AUTOSAR XML (schema 4-2-2)
package /STELLANTIS/EPT/ASWCs
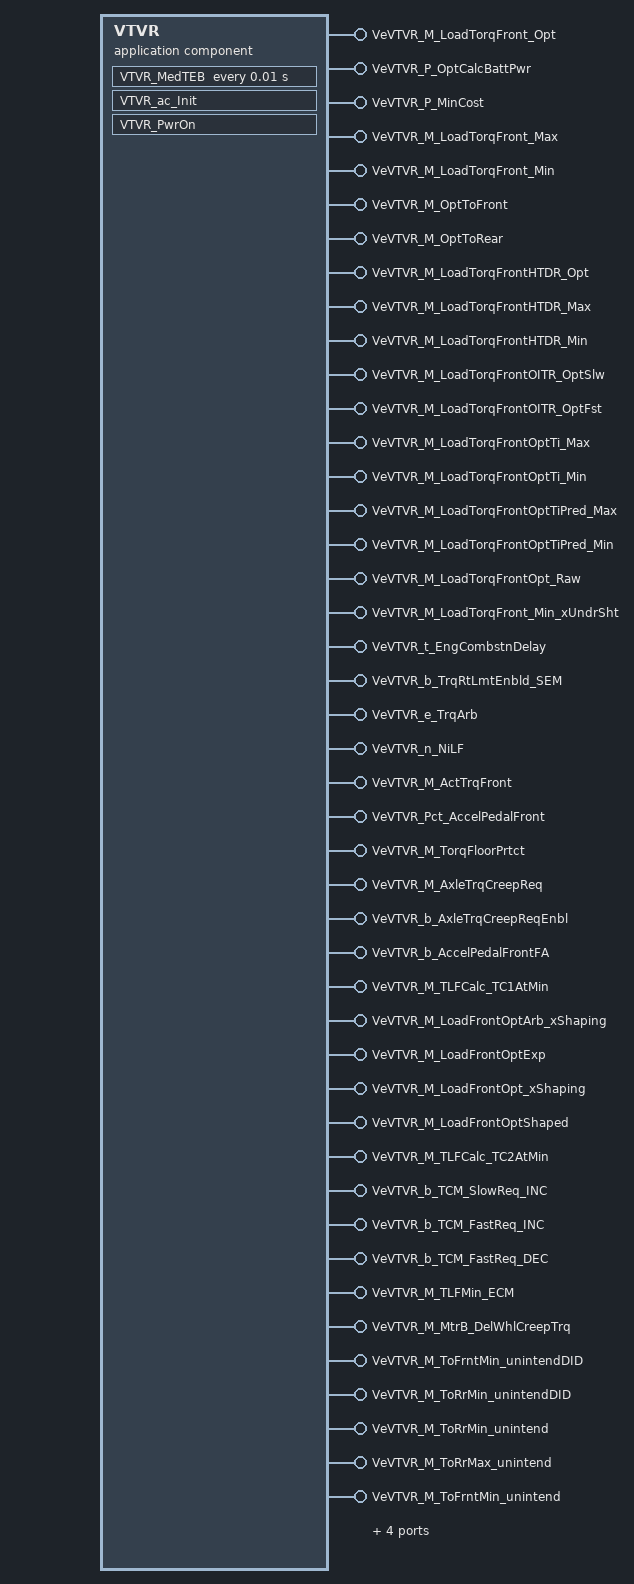
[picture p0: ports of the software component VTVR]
  application sw component type VTVR
    48 x provide port:
      VeVTVR_M_LoadTorqFront_Opt: nonqueued-sender-com-spec{data-element=Value, init-value=0}, provided-interface=VeVTVR_M_LoadTorqFront_Opt
      VeVTVR_P_OptCalcBattPwr: nonqueued-sender-com-spec{data-element=Value, init-value=0}, provided-interface=VeVTVR_P_OptCalcBattPwr
      VeVTVR_P_MinCost: nonqueued-sender-com-spec{data-element=Value, init-value=0}, provided-interface=VeVTVR_P_MinCost
      VeVTVR_M_LoadTorqFront_Max: nonqueued-sender-com-spec{data-element=Value, init-value=0}, provided-interface=VeVTVR_M_LoadTorqFront_Max
      VeVTVR_M_LoadTorqFront_Min: nonqueued-sender-com-spec{data-element=Value, init-value=0}, provided-interface=VeVTVR_M_LoadTorqFront_Min
      VeVTVR_M_OptToFront: nonqueued-sender-com-spec{data-element=Value, init-value=0}, provided-interface=VeVTVR_M_OptToFront
      VeVTVR_M_OptToRear: nonqueued-sender-com-spec{data-element=Value, init-value=0}, provided-interface=VeVTVR_M_OptToRear
      VeVTVR_M_LoadTorqFrontHTDR_Opt: nonqueued-sender-com-spec{data-element=Value, init-value=0}, provided-interface=VeVTVR_M_LoadTorqFrontHTDR_Opt
      VeVTVR_M_LoadTorqFrontHTDR_Max: nonqueued-sender-com-spec{data-element=Value, init-value=0}, provided-interface=VeVTVR_M_LoadTorqFrontHTDR_Max
      VeVTVR_M_LoadTorqFrontHTDR_Min: nonqueued-sender-com-spec{data-element=Value, init-value=0}, provided-interface=VeVTVR_M_LoadTorqFrontHTDR_Min
      VeVTVR_M_LoadTorqFrontOITR_OptSlw: nonqueued-sender-com-spec{data-element=Value, init-value=0}, provided-interface=VeVTVR_M_LoadTorqFrontOITR_OptSlw
      VeVTVR_M_LoadTorqFrontOITR_OptFst: nonqueued-sender-com-spec{data-element=Value, init-value=0}, provided-interface=VeVTVR_M_LoadTorqFrontOITR_OptFst
      VeVTVR_M_LoadTorqFrontOptTi_Max: nonqueued-sender-com-spec{data-element=Value, init-value=0}, provided-interface=VeVTVR_M_LoadTorqFrontOptTi_Max
      VeVTVR_M_LoadTorqFrontOptTi_Min: nonqueued-sender-com-spec{data-element=Value, init-value=0}, provided-interface=VeVTVR_M_LoadTorqFrontOptTi_Min
      VeVTVR_M_LoadTorqFrontOptTiPred_Max: nonqueued-sender-com-spec{data-element=Value, init-value=0}, provided-interface=VeVTVR_M_LoadTorqFrontOptTiPred_Max
      VeVTVR_M_LoadTorqFrontOptTiPred_Min: nonqueued-sender-com-spec{data-element=Value, init-value=0}, provided-interface=VeVTVR_M_LoadTorqFrontOptTiPred_Min
      VeVTVR_M_LoadTorqFrontOpt_Raw: nonqueued-sender-com-spec{data-element=Value, init-value=0}, provided-interface=VeVTVR_M_LoadTorqFrontOpt_Raw
      VeVTVR_M_LoadTorqFront_Min_xUndrSht: nonqueued-sender-com-spec{data-element=Value, init-value=0}, provided-interface=VeVTVR_M_LoadTorqFront_Min_xUndrSht
      VeVTVR_t_EngCombstnDelay: nonqueued-sender-com-spec{data-element=Value, init-value=0}, provided-interface=VeVTVR_t_EngCombstnDelay
      VeVTVR_b_TrqRtLmtEnbld_SEM: nonqueued-sender-com-spec{data-element=Value, init-value=0}, provided-interface=VeVTVR_b_TrqRtLmtEnbld_SEM
      VeVTVR_e_TrqArb: nonqueued-sender-com-spec{data-element=Value, init-value=CeWTAR_e_ECM_TorqReqst}, provided-interface=VeVTVR_e_TrqArb
      VeVTVR_n_NiLF: nonqueued-sender-com-spec{data-element=Value, init-value=0}, provided-interface=VeVTVR_n_NiLF
      VeVTVR_M_ActTrqFront: nonqueued-sender-com-spec{data-element=Value, init-value=0}, provided-interface=VeVTVR_M_ActTrqFront
      VeVTVR_Pct_AccelPedalFront: nonqueued-sender-com-spec{data-element=Value, init-value=0}, provided-interface=VeVTVR_Pct_AccelPedalFront
      VeVTVR_M_TorqFloorPrtct: nonqueued-sender-com-spec{data-element=Value, init-value=0}, provided-interface=VeVTVR_M_TorqFloorPrtct
      VeVTVR_M_AxleTrqCreepReq: nonqueued-sender-com-spec{data-element=Value, init-value=0}, provided-interface=VeVTVR_M_AxleTrqCreepReq
      VeVTVR_b_AxleTrqCreepReqEnbl: nonqueued-sender-com-spec{data-element=Value, init-value=0}, provided-interface=VeVTVR_b_AxleTrqCreepReqEnbl
      VeVTVR_b_AccelPedalFrontFA: nonqueued-sender-com-spec{data-element=Value, init-value=0}, provided-interface=VeVTVR_b_AccelPedalFrontFA
      VeVTVR_M_TLFCalc_TC1AtMin: nonqueued-sender-com-spec{data-element=Value, init-value=0}, provided-interface=VeVTVR_M_TLFCalc_TC1AtMin
      VeVTVR_M_LoadFrontOptArb_xShaping: nonqueued-sender-com-spec{data-element=Value, init-value=0}, provided-interface=VeVTVR_M_LoadFrontOptArb_xShaping
      VeVTVR_M_LoadFrontOptExp: nonqueued-sender-com-spec{data-element=Value, init-value=0}, provided-interface=VeVTVR_M_LoadFrontOptExp
      VeVTVR_M_LoadFrontOpt_xShaping: nonqueued-sender-com-spec{data-element=Value, init-value=0}, provided-interface=VeVTVR_M_LoadFrontOpt_xShaping
      VeVTVR_M_LoadFrontOptShaped: nonqueued-sender-com-spec{data-element=Value, init-value=0}, provided-interface=VeVTVR_M_LoadFrontOptShaped
      VeVTVR_M_TLFCalc_TC2AtMin: nonqueued-sender-com-spec{data-element=Value, init-value=0}, provided-interface=VeVTVR_M_TLFCalc_TC2AtMin
      VeVTVR_b_TCM_SlowReq_INC: nonqueued-sender-com-spec{data-element=Value, init-value=0}, provided-interface=VeVTVR_b_TCM_SlowReq_INC
      VeVTVR_b_TCM_FastReq_INC: nonqueued-sender-com-spec{data-element=Value, init-value=0}, provided-interface=VeVTVR_b_TCM_FastReq_INC
      VeVTVR_b_TCM_FastReq_DEC: nonqueued-sender-com-spec{data-element=Value, init-value=0}, provided-interface=VeVTVR_b_TCM_FastReq_DEC
      VeVTVR_M_TLFMin_ECM: nonqueued-sender-com-spec{data-element=Value, init-value=0}, provided-interface=VeVTVR_M_TLFMin_ECM
      VeVTVR_M_MtrB_DelWhlCreepTrq: nonqueued-sender-com-spec{data-element=Value, init-value=0}, provided-interface=VeVTVR_M_MtrB_DelWhlCreepTrq
      VeVTVR_M_ToFrntMin_unintendDID: nonqueued-sender-com-spec{data-element=Value, init-value=0}, provided-interface=VeVTVR_M_ToFrntMin_unintendDID
      VeVTVR_M_ToRrMin_unintendDID: nonqueued-sender-com-spec{data-element=Value, init-value=0}, provided-interface=VeVTVR_M_ToRrMin_unintendDID
      VeVTVR_M_ToRrMin_unintend: nonqueued-sender-com-spec{data-element=Value, init-value=0}, provided-interface=VeVTVR_M_ToRrMin_unintend
      VeVTVR_M_ToRrMax_unintend: nonqueued-sender-com-spec{data-element=Value, init-value=0}, provided-interface=VeVTVR_M_ToRrMax_unintend
      VeVTVR_M_ToFrntMin_unintend: nonqueued-sender-com-spec{data-element=Value, init-value=0}, provided-interface=VeVTVR_M_ToFrntMin_unintend
      VeVTVR_M_ToFrntMax_unintend: nonqueued-sender-com-spec{data-element=Value, init-value=0}, provided-interface=VeVTVR_M_ToFrntMax_unintend
      VeVTVR_M_SumTrqMin_Cruise: nonqueued-sender-com-spec{data-element=Value, init-value=0}, provided-interface=VeVTVR_M_SumTrqMin_Cruise
      VeVTVR_M_OutTorqReqModTactMax: nonqueued-sender-com-spec{data-element=Value, init-value=0}, provided-interface=VeVTVR_M_OutTorqReqModTactMax
      VeVTVR_M_OutTorqReqModTactMin: nonqueued-sender-com-spec{data-element=Value, init-value=0}, provided-interface=VeVTVR_M_OutTorqReqModTactMin
    behavior IB_VTVR: data-type-mapping=msADTtoIDTMapping, handle-termination-and-restart=NO-SUPPORT, included-data-type-set=data-type=[TeOPTR_e_OptType, TeTSXR_e_PrfrdComb]
      timing event Event_MedTEB: start-on-event=VTVR_MedTEB, period=0.01
      init event Event_VTVR_ac_Init: start-on-event=VTVR_ac_Init
      init event Event_PwrOn: start-on-event=VTVR_PwrOn
      runnable VTVR_ac_Init
        data-send-points:
          access OUT_VeVTVR_M_TLFCalc_TC1AtMin_Value: accessed-variable=VeVTVR_M_TLFCalc_TC1AtMin.Value
          access OUT_VeVTVR_e_TrqArb_Value: accessed-variable=VeVTVR_e_TrqArb.Value
      runnable VTVR_PwrOn
        data-send-points:
          48 x access:
            OUT_VeVTVR_M_ActTrqFront_Value: accessed-variable=VeVTVR_M_ActTrqFront.Value
            OUT_VeVTVR_Pct_AccelPedalFront_Value: accessed-variable=VeVTVR_Pct_AccelPedalFront.Value
            OUT_VeVTVR_M_OptToFront_Value: accessed-variable=VeVTVR_M_OptToFront.Value
            OUT_VeVTVR_M_OptToRear_Value: accessed-variable=VeVTVR_M_OptToRear.Value
            OUT_VeVTVR_n_NiLF_Value: accessed-variable=VeVTVR_n_NiLF.Value
            OUT_VeVTVR_M_AxleTrqCreepReq_Value: accessed-variable=VeVTVR_M_AxleTrqCreepReq.Value
            OUT_VeVTVR_b_AxleTrqCreepReqEnbl_Value: accessed-variable=VeVTVR_b_AxleTrqCreepReqEnbl.Value
            OUT_VeVTVR_b_AccelPedalFrontFA_Value: accessed-variable=VeVTVR_b_AccelPedalFrontFA.Value
            OUT_VeVTVR_M_LoadFrontOptShaped_Value: accessed-variable=VeVTVR_M_LoadFrontOptShaped.Value
            OUT_VeVTVR_M_TLFCalc_TC1AtMin_Value: accessed-variable=VeVTVR_M_TLFCalc_TC1AtMin.Value
            OUT_VeVTVR_b_TrqRtLmtEnbld_SEM_Value: accessed-variable=VeVTVR_b_TrqRtLmtEnbld_SEM.Value
            OUT_VeVTVR_t_EngCombstnDelay_Value: accessed-variable=VeVTVR_t_EngCombstnDelay.Value
            OUT_VeVTVR_M_LoadTorqFront_Min_xUndrSht_Value: accessed-variable=VeVTVR_M_LoadTorqFront_Min_xUndrSht.Value
            OUT_VeVTVR_M_LoadTorqFrontOpt_Raw_Value: accessed-variable=VeVTVR_M_LoadTorqFrontOpt_Raw.Value
            OUT_VeVTVR_M_TLFCalc_TC2AtMin_Value: accessed-variable=VeVTVR_M_TLFCalc_TC2AtMin.Value
            OUT_VeVTVR_M_LoadTorqFront_Min_Value: accessed-variable=VeVTVR_M_LoadTorqFront_Min.Value
            OUT_VeVTVR_M_LoadTorqFrontOITR_OptSlw_Value: accessed-variable=VeVTVR_M_LoadTorqFrontOITR_OptSlw.Value
            OUT_VeVTVR_M_TLFMin_ECM_Value: accessed-variable=VeVTVR_M_TLFMin_ECM.Value
            OUT_VeVTVR_M_MtrB_DelWhlCreepTrq_Value: accessed-variable=VeVTVR_M_MtrB_DelWhlCreepTrq.Value
            OUT_VeVTVR_M_LoadFrontOpt_xShaping_Value: accessed-variable=VeVTVR_M_LoadFrontOpt_xShaping.Value
            OUT_VeVTVR_M_ToFrntMin_unintendDID_Value: accessed-variable=VeVTVR_M_ToFrntMin_unintendDID.Value
            OUT_VeVTVR_M_LoadFrontOptExp_Value: accessed-variable=VeVTVR_M_LoadFrontOptExp.Value
            OUT_VeVTVR_M_ToRrMin_unintendDID_Value: accessed-variable=VeVTVR_M_ToRrMin_unintendDID.Value
            OUT_VeVTVR_M_ToRrMin_unintend_Value: accessed-variable=VeVTVR_M_ToRrMin_unintend.Value
            OUT_VeVTVR_M_ToRrMax_unintend_Value: accessed-variable=VeVTVR_M_ToRrMax_unintend.Value
            OUT_VeVTVR_M_ToFrntMin_unintend_Value: accessed-variable=VeVTVR_M_ToFrntMin_unintend.Value
            OUT_VeVTVR_M_ToFrntMax_unintend_Value: accessed-variable=VeVTVR_M_ToFrntMax_unintend.Value
            OUT_VeVTVR_M_SumTrqMin_Cruise_Value: accessed-variable=VeVTVR_M_SumTrqMin_Cruise.Value
            OUT_VeVTVR_M_LoadTorqFront_Max_Value: accessed-variable=VeVTVR_M_LoadTorqFront_Max.Value
            OUT_VeVTVR_M_LoadTorqFront_Opt_Value: accessed-variable=VeVTVR_M_LoadTorqFront_Opt.Value
            OUT_VeVTVR_M_LoadTorqFrontHTDR_Max_Value: accessed-variable=VeVTVR_M_LoadTorqFrontHTDR_Max.Value
            OUT_VeVTVR_M_LoadFrontOptArb_xShaping_Value: accessed-variable=VeVTVR_M_LoadFrontOptArb_xShaping.Value
            OUT_VeVTVR_M_LoadTorqFrontHTDR_Min_Value: accessed-variable=VeVTVR_M_LoadTorqFrontHTDR_Min.Value
            OUT_VeVTVR_M_LoadTorqFrontOptTi_Max_Value: accessed-variable=VeVTVR_M_LoadTorqFrontOptTi_Max.Value
            OUT_VeVTVR_M_LoadTorqFrontOptTi_Min_Value: accessed-variable=VeVTVR_M_LoadTorqFrontOptTi_Min.Value
            OUT_VeVTVR_M_LoadTorqFrontOptTiPred_Max_Value: accessed-variable=VeVTVR_M_LoadTorqFrontOptTiPred_Max.Value
            OUT_VeVTVR_M_LoadTorqFrontOptTiPred_Min_Value: accessed-variable=VeVTVR_M_LoadTorqFrontOptTiPred_Min.Value
            OUT_VeVTVR_b_TCM_SlowReq_INC_Value: accessed-variable=VeVTVR_b_TCM_SlowReq_INC.Value
            OUT_VeVTVR_b_TCM_FastReq_INC_Value: accessed-variable=VeVTVR_b_TCM_FastReq_INC.Value
            OUT_VeVTVR_b_TCM_FastReq_DEC_Value: accessed-variable=VeVTVR_b_TCM_FastReq_DEC.Value
            OUT_VeVTVR_M_LoadTorqFrontOITR_OptFst_Value: accessed-variable=VeVTVR_M_LoadTorqFrontOITR_OptFst.Value
            OUT_VeVTVR_M_LoadTorqFrontHTDR_Opt_Value: accessed-variable=VeVTVR_M_LoadTorqFrontHTDR_Opt.Value
            OUT_VeVTVR_e_TrqArb_Value: accessed-variable=VeVTVR_e_TrqArb.Value
            OUT_VeVTVR_P_OptCalcBattPwr_Value: accessed-variable=VeVTVR_P_OptCalcBattPwr.Value
            OUT_VeVTVR_P_MinCost_Value: accessed-variable=VeVTVR_P_MinCost.Value
            OUT_VeVTVR_M_TorqFloorPrtct_Value: accessed-variable=VeVTVR_M_TorqFloorPrtct.Value
            OUT_VeVTVR_M_OutTorqReqModTactMax_Value: accessed-variable=VeVTVR_M_OutTorqReqModTactMax.Value
            OUT_VeVTVR_M_OutTorqReqModTactMin_Value: accessed-variable=VeVTVR_M_OutTorqReqModTactMin.Value
      runnable VTVR_MedTEB
        data-send-points:
          48 x access:
            OUT_VeVTVR_M_TLFMin_ECM_Value: accessed-variable=VeVTVR_M_TLFMin_ECM.Value
            OUT_VeVTVR_M_ToFrntMin_unintendDID_Value: accessed-variable=VeVTVR_M_ToFrntMin_unintendDID.Value
            OUT_VeVTVR_M_ToRrMin_unintendDID_Value: accessed-variable=VeVTVR_M_ToRrMin_unintendDID.Value
            OUT_VeVTVR_M_ToRrMin_unintend_Value: accessed-variable=VeVTVR_M_ToRrMin_unintend.Value
            OUT_VeVTVR_M_ToRrMax_unintend_Value: accessed-variable=VeVTVR_M_ToRrMax_unintend.Value
            OUT_VeVTVR_M_ToFrntMin_unintend_Value: accessed-variable=VeVTVR_M_ToFrntMin_unintend.Value
            OUT_VeVTVR_M_ToFrntMax_unintend_Value: accessed-variable=VeVTVR_M_ToFrntMax_unintend.Value
            OUT_VeVTVR_M_TorqFloorPrtct_Value: accessed-variable=VeVTVR_M_TorqFloorPrtct.Value
            OUT_VeVTVR_M_OutTorqReqModTactMax_Value: accessed-variable=VeVTVR_M_OutTorqReqModTactMax.Value
            OUT_VeVTVR_M_OutTorqReqModTactMin_Value: accessed-variable=VeVTVR_M_OutTorqReqModTactMin.Value
            OUT_VeVTVR_M_OptToFront_Value: accessed-variable=VeVTVR_M_OptToFront.Value
            OUT_VeVTVR_M_OptToRear_Value: accessed-variable=VeVTVR_M_OptToRear.Value
            OUT_VeVTVR_M_TLFCalc_TC1AtMin_Value: accessed-variable=VeVTVR_M_TLFCalc_TC1AtMin.Value
            OUT_VeVTVR_M_TLFCalc_TC2AtMin_Value: accessed-variable=VeVTVR_M_TLFCalc_TC2AtMin.Value
            OUT_VeVTVR_P_OptCalcBattPwr_Value: accessed-variable=VeVTVR_P_OptCalcBattPwr.Value
            OUT_VeVTVR_P_MinCost_Value: accessed-variable=VeVTVR_P_MinCost.Value
            OUT_VeVTVR_n_NiLF_Value: accessed-variable=VeVTVR_n_NiLF.Value
            OUT_VeVTVR_M_LoadTorqFrontOITR_OptSlw_Value: accessed-variable=VeVTVR_M_LoadTorqFrontOITR_OptSlw.Value
            OUT_VeVTVR_M_LoadTorqFrontHTDR_Max_Value: accessed-variable=VeVTVR_M_LoadTorqFrontHTDR_Max.Value
            OUT_VeVTVR_M_LoadTorqFrontHTDR_Min_Value: accessed-variable=VeVTVR_M_LoadTorqFrontHTDR_Min.Value
            OUT_VeVTVR_M_LoadTorqFrontOptTi_Max_Value: accessed-variable=VeVTVR_M_LoadTorqFrontOptTi_Max.Value
            OUT_VeVTVR_M_LoadTorqFrontOptTi_Min_Value: accessed-variable=VeVTVR_M_LoadTorqFrontOptTi_Min.Value
            OUT_VeVTVR_M_LoadTorqFrontOptTiPred_Max_Value: accessed-variable=VeVTVR_M_LoadTorqFrontOptTiPred_Max.Value
            OUT_VeVTVR_M_LoadTorqFrontOptTiPred_Min_Value: accessed-variable=VeVTVR_M_LoadTorqFrontOptTiPred_Min.Value
            OUT_VeVTVR_b_TCM_SlowReq_INC_Value: accessed-variable=VeVTVR_b_TCM_SlowReq_INC.Value
            OUT_VeVTVR_b_TCM_FastReq_INC_Value: accessed-variable=VeVTVR_b_TCM_FastReq_INC.Value
            OUT_VeVTVR_b_TCM_FastReq_DEC_Value: accessed-variable=VeVTVR_b_TCM_FastReq_DEC.Value
            OUT_VeVTVR_M_LoadTorqFrontOITR_OptFst_Value: accessed-variable=VeVTVR_M_LoadTorqFrontOITR_OptFst.Value
            OUT_VeVTVR_M_LoadTorqFrontHTDR_Opt_Value: accessed-variable=VeVTVR_M_LoadTorqFrontHTDR_Opt.Value
            OUT_VeVTVR_M_ActTrqFront_Value: accessed-variable=VeVTVR_M_ActTrqFront.Value
            OUT_VeVTVR_Pct_AccelPedalFront_Value: accessed-variable=VeVTVR_Pct_AccelPedalFront.Value
            OUT_VeVTVR_M_AxleTrqCreepReq_Value: accessed-variable=VeVTVR_M_AxleTrqCreepReq.Value
            OUT_VeVTVR_b_AxleTrqCreepReqEnbl_Value: accessed-variable=VeVTVR_b_AxleTrqCreepReqEnbl.Value
            OUT_VeVTVR_b_AccelPedalFrontFA_Value: accessed-variable=VeVTVR_b_AccelPedalFrontFA.Value
            OUT_VeVTVR_M_LoadFrontOptShaped_Value: accessed-variable=VeVTVR_M_LoadFrontOptShaped.Value
            OUT_VeVTVR_b_TrqRtLmtEnbld_SEM_Value: accessed-variable=VeVTVR_b_TrqRtLmtEnbld_SEM.Value
            OUT_VeVTVR_t_EngCombstnDelay_Value: accessed-variable=VeVTVR_t_EngCombstnDelay.Value
            OUT_VeVTVR_M_LoadTorqFront_Min_xUndrSht_Value: accessed-variable=VeVTVR_M_LoadTorqFront_Min_xUndrSht.Value
            OUT_VeVTVR_M_LoadTorqFrontOpt_Raw_Value: accessed-variable=VeVTVR_M_LoadTorqFrontOpt_Raw.Value
            OUT_VeVTVR_M_LoadTorqFront_Min_Value: accessed-variable=VeVTVR_M_LoadTorqFront_Min.Value
            OUT_VeVTVR_M_LoadFrontOpt_xShaping_Value: accessed-variable=VeVTVR_M_LoadFrontOpt_xShaping.Value
            OUT_VeVTVR_M_LoadFrontOptExp_Value: accessed-variable=VeVTVR_M_LoadFrontOptExp.Value
            OUT_VeVTVR_M_SumTrqMin_Cruise_Value: accessed-variable=VeVTVR_M_SumTrqMin_Cruise.Value
            OUT_VeVTVR_M_LoadTorqFront_Max_Value: accessed-variable=VeVTVR_M_LoadTorqFront_Max.Value
            OUT_VeVTVR_M_LoadTorqFront_Opt_Value: accessed-variable=VeVTVR_M_LoadTorqFront_Opt.Value
            OUT_VeVTVR_M_LoadFrontOptArb_xShaping_Value: accessed-variable=VeVTVR_M_LoadFrontOptArb_xShaping.Value
            OUT_VeVTVR_e_TrqArb_Value: accessed-variable=VeVTVR_e_TrqArb.Value
            OUT_VeVTVR_M_MtrB_DelWhlCreepTrq_Value: accessed-variable=VeVTVR_M_MtrB_DelWhlCreepTrq.Value
      28 x variation point proxy:
        Variant_HSCL_3Mot_Enbl: category=CONDITION, condition-access=0
        Variant_HSCL_BstConvEnbl: category=CONDITION, condition-access=0
        Variant_HSCL_SEMArbEnbl: category=CONDITION, condition-access=0
        Variant_HSCR_TorqueFloor_1: category=CONDITION, condition-access=0
        Variant_HSCR_UseAdherenceLim_1: category=CONDITION, condition-access=1
        Variant_OPTL_3MtrEnbl: category=CONDITION, condition-access=0
        Variant_OPTL_ABOCase_BEV: category=CONDITION, condition-access=1
        Variant_OPTL_ABOCase_FullABO: category=CONDITION, condition-access=0
        Variant_OPTL_ABPtsEnbl: category=CONDITION, condition-access=1
        Variant_OPTL_EPtsEnbl: category=CONDITION, condition-access=1
        Variant_OPTL_HPtEnbl: category=CONDITION, condition-access=1
        Variant_OPTL_HPtEnbl_ToMinMax: category=CONDITION, condition-access=1
        Variant_OPTL_LegacyModeCnst: category=CONDITION, condition-access=1
        Variant_VTVR_AxleBased_Flavor: category=CONDITION, condition-access=0
        Variant_VTVR_FUNC_1: category=CONDITION, condition-access=0
        Variant_VTVR_FUNC_10: category=CONDITION, condition-access=1
        Variant_VTVR_FUNC_12: category=CONDITION, condition-access=0
        Variant_VTVR_FUNC_14: category=CONDITION, condition-access=0
        Variant_VTVR_FUNC_3: category=CONDITION, condition-access=1
        Variant_VTVR_FUNC_5: category=CONDITION, condition-access=1
        Variant_VTVR_FUNC_7: category=CONDITION, condition-access=1
        Variant_VTVR_FUNC_ChrgTrqTrig: category=CONDITION, condition-access=0
        Variant_VTVR_FUNC_GSEnbl: category=CONDITION, condition-access=0
        Variant_VTVR_FUNC_ProcessOutputTrig: category=CONDITION, condition-access=0
        Variant_VTVR_FUNC_TrqFlrEnblTrig: category=CONDITION, condition-access=0
        Variant_VTVR_FUNC_VirtualPdlTrig: category=CONDITION, condition-access=0
        Variant_VTVR_SumBased_Flavor: category=CONDITION, condition-access=0
        XeVTVR_b_GSEnbl: category=VALUE, value-access=boolean-value-variation-point=0
